# psoc4100sp256kb register map
Vendor: Infineon Technologies; Series: PSOC4100Sp256KB; File version: 1.0
CPU: CM0PLUS r0p1, little endian, MPU, no FPU, VTOR, 2 interrupt priority bits, 29 interrupts
Registers are 32-bit, read-write, reset 0x0 unless marked. A register's access mark holds for its fields unless they carry their own. Offsets are from the block's base; [hi:lo] are bit positions; lines under a group give offsets from that group; {n}, {i} and the like mark numbered series; <NAME> marks a mode.

## PRGIO — Programmable IO configuration
Base 0x40050000
{0x0+0x100*i} PRT[{i}] (i=0..1) group — Programmable IO port registers
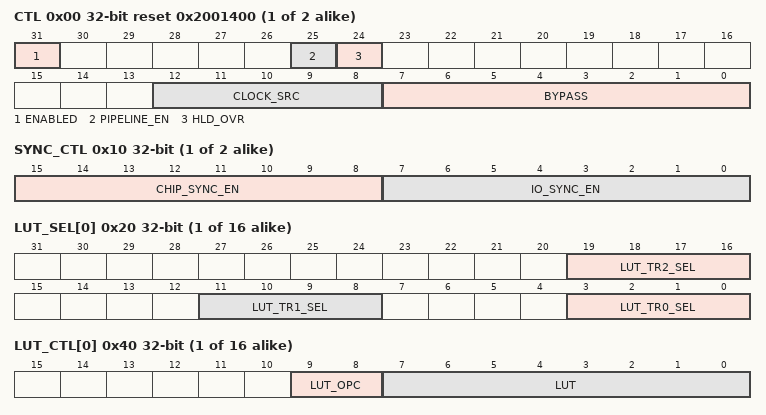
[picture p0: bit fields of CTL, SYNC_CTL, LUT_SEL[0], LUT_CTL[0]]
  0x00 CTL reset 0x2001400 (reset mask 0x82001F00) — Control register
    [31] ENABLED — Enable for programmable IO. Should only be set to '1' when the programmable IO is completely configured: '0': Disabled (signals are bypassed; behavior as if BYPASS is 0xFF). When disabled, the fabric (data unit and LUTs) reset is activated. If the IP is disabled: - The PIPELINE_EN register field should be set to '1', to ensure low power consumption by preventing combinatorial loops. - The CLOCK_SRC register field should be set to '20'-'30' (clock is constant '0'), to ensure low power consumption. '1': Enabled. Once enabled, it takes 3 'clk_fabric' clock cycles till the fabric reset is de-activated and the fabric becomes fully functional. This ensures that the IO pins' input synchronizer states are flushed when the fabric is fully functional.
    [25] PIPELINE_EN — Enable for pipeline register: '0': Disabled (register is bypassed). '1': Enabled.
    [24] HLD_OVR — IO cell hold override functionality. In DeepSleep and Hibernate power modes, the HSIOM holds the IO cell output and output enable signals if Active functionality is connected to the IO pads. This is undesirable if the PRGIO is supposed to deliver DeepSleep or Hibernate output functionality on these IO pads. This field is used to control the hold override functionality from the PRGIO: '0': The HSIOM controls the IO cell hold override functionality ('hsiom_hld_ovr'). '1': The PRGIO controls the IO cel hold override functionality: - In bypass mode (ENABLED is '0' or BYPASS[i] is '1'), the HSIOM control is used. - In NON bypass mode (ENABLED is '1' and BYPASS[i] is '0'), the PRGIO sets hold override to 'pwr_hld_ovr_hib' to enable PRGIO functionality in DeepSleep and Hibernate power modes (but disables it in Stop power mode). Note that in Hibernate power mode, the PRGIO should not rely on the state of Active or DeepSleep functionality signals from the HSIOM: these signals are clamped to '0' in Hibernate'
    [12:8] CLOCK_SRC — Clock ('clk_fabric') and reset ('rst_fabric_n') source selection: '0': io_data_in[0]/'1'. ... '7': io_data_in[7]/'1'. '8': chip_data[0]/'1'. ... '15': chip_data[7]/'1'. '16': clk_prgio/rst_sys_act_n. Used for both Active functionality synchronous logic on 'clk_prgio'. This selection is intended for synchronous operation on a PCLK specified clock frequency ('clock_prgio_en'). Note that the fabric's clocked elements are frequency aligned, but NOT phase aligned to 'clk_sys'. '17': clk_prgio/rst_sys_dpslp_n. Used for both DeepSleep functionality synchronous logic on 'clk_prgio' (note that 'clk_prgio' is NOT available in DeepSleep and Hibernate power modes). This selection is intended for synchronous operation on a PCLK specified clock frequency ('clock_prgio_en'). Note that the fabric's clocked elements are frequency aligned, but NOT phase aligned to 'clk_sys'. '18': clk_prgio/rst_sys_hib_n. Used for both Hibernate functionality synchronous logic on 'clk_prgio' (note that 'clk_prgio' is NOT available in DeepSleep and Hibernate power modes). This selection is intended for synchronous operation on a PCLK specified clock frequency ('clock_prgio_en'). Note that the fabric's clocked elements are frequency aligned, but NOT phase aligned to 'clk_sys'. '19': clk_lf/rst_lf_dpslp_n (note that 'clk_lf' is only available in DeepSleep power mode). This selection is intended for synchronous operation on'clk_lf'. Note that the fabric's clocked elements are frequency aligned, but NOT phase aligned to other 'clk_lf' clocked elements. '20'-'30': Clock source is constant '0'. Any of these clock sources should be selected when the IP is disabled to ensure low power consumption. '31': clk_sys/'1'. This selection is NOT intended for 'clk_sys' operation, but for asynchronous operation: three 'clk_sys' cycles after enabling the IP, the IP is fully functional (reset is de-activated). To be used for asynchronous (clockless) fabric functionality.
    [7:0] BYPASS — Bypass of the programmable IO, one bit for each IO pin: BYPASS[i] is for IO pin i. When ENABLED is '1', this field is used. When ENABLED is '0', this field is NOT used and PRGIO is always bypassed. '0': No bypass (programmable IO fabric is exposed). '1': Bypass (programmable IO fabric is hidden).
  0x10 SYNC_CTL reset not defined — Synchronization control register
    [15:8] CHIP_SYNC_EN — Synchronization of the chip input signals to 'clk_fabric', one bit for each input: CHIP_SYNC_EN[i] is for input i. '0': No synchronization. '1': Synchronization.
    [7:0] IO_SYNC_EN — Synchronization of the IO pin input signals to 'clk_fabric', one bit for each IO pin: IO_SYNC_EN[i] is for IO pin i. '0': No synchronization. '1': Synchronization.
  {0x20+4j} LUT_SEL[{j}] (j=0..7) reset not defined — LUT component input selection
    [19:16] LUT_TR2_SEL — LUT input signal 'tr2_in' source selection. Encoding is the same as for LUT_TR1_SEL.
    [11:8] LUT_TR1_SEL — LUT input signal 'tr1_in' source selection: '0': LUT 0 output. '1': LUT 1 output. '2': LUT 2 output. '3': LUT 3 output. '4': LUT 4 output. '5': LUT 5 output. '6': LUT 6 output. '7': LUT 7 output. '8': chip_data[0] (for LUTs 0, 1, 2, 3); chip_data[4] (for LUTs 4, 5, 6, 7). '9': chip_data[1] (for LUTs 0, 1, 2, 3); chip_data[5] (for LUTs 4, 5, 6, 7). '10': chip_data[2] (for LUTs 0, 1, 2, 3); chip_data[6] (for LUTs 4, 5, 6, 7). '11': chip_data[3] (for LUTs 0, 1, 2, 3); chip_data[7] (for LUTs 4, 5, 6, 7). '12': io_data_in[0] (for LUTs 0, 1, 2, 3); io_data_in[4] (for LUTs 4, 5, 6, 7). '13': io_data_in[1] (for LUTs 0, 1, 2, 3); io_data_in[5] (for LUTs 4, 5, 6, 7). '14': io_data_in[2] (for LUTs 0, 1, 2, 3); io_data_in[6] (for LUTs 4, 5, 6, 7). '15': io_data_in[3] (for LUTs 0, 1, 2, 3); io_data_in[7] (for LUTs 4, 5, 6, 7).
    [3:0] LUT_TR0_SEL — LUT input signal 'tr0_in' source selection: '0': Data unit output. '1': LUT 1 output. '2': LUT 2 output. '3': LUT 3 output. '4': LUT 4 output. '5': LUT 5 output. '6': LUT 6 output. '7': LUT 7 output. '8': chip_data[0] (for LUTs 0, 1, 2, 3); chip_data[4] (for LUTs 4, 5, 6, 7). '9': chip_data[1] (for LUTs 0, 1, 2, 3); chip_data[5] (for LUTs 4, 5, 6, 7). '10': chip_data[2] (for LUTs 0, 1, 2, 3); chip_data[6] (for LUTs 4, 5, 6, 7). '11': chip_data[3] (for LUTs 0, 1, 2, 3); chip_data[7] (for LUTs 4, 5, 6, 7). '12': io_data_in[0] (for LUTs 0, 1, 2, 3); io_data_in[4] (for LUTs 4, 5, 6, 7). '13': io_data_in[1] (for LUTs 0, 1, 2, 3); io_data_in[5] (for LUTs 4, 5, 6, 7). '14': io_data_in[2] (for LUTs 0, 1, 2, 3); io_data_in[6] (for LUTs 4, 5, 6, 7). '15': io_data_in[3] (for LUTs 0, 1, 2, 3); io_data_in[7] (for LUTs 4, 5, 6, 7).
  {0x40+4j} LUT_CTL[{j}] (j=0..7) reset not defined — LUT component control register
    [9:8] LUT_OPC — LUT opcode specifies the LUT operation: '0': Combinatoral output, no feedback. tr_out = LUT[{tr2_in, tr1_in, tr0_in}]. '1': Combinatorial output, feedback. tr_out = LUT[{lut_reg, tr1_in, tr0_in}]. On clock: lut_reg <= tr_in2. '2': Sequential output, no feedback. temp = LUT[{tr2_in, tr1_in, tr0_in}]. tr_out = lut_reg. On clock: lut_reg <= temp. '3': Register with asynchronous set and reset. tr_out = lut_reg. enable = (tr2_in ^ LUT[4]) | LUT[5]. set = enable & (tr1_in ^ LUT[2]) & LUT[3]. clr = enable & (tr0_in ^ LUT[0]) & LUT[1]. Asynchronously (no clock required): lut_reg <= if (clr) '0' else if (set) '1'
    [7:0] LUT — LUT configuration. Depending on the LUT opcode LUT_OPC, the internal state lut_reg (captured in a flip-flop) and the LUT input signals tr0_in, tr1_in, tr2_in, the LUT configuration is used to determine the LUT output signal and the next sequential state (lut_reg).
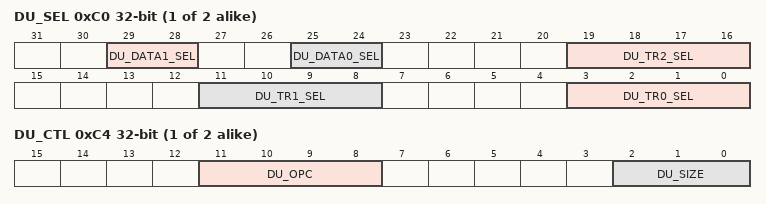
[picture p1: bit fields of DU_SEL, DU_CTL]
  0xC0 DU_SEL reset not defined — Data unit component input selection
    [29:28] DU_DATA1_SEL — Data unit input data 'data1_in' source selection. Encoding is the same as for DU_DATA0_SEL.
    [25:24] DU_DATA0_SEL — Data unit input data 'data0_in' source selection: '0': Constant '0'. '1': chip_data[7:0]. '2': io_data_in[7:0]. '3': DATA.DATA MMIO register field.
    [19:16] DU_TR2_SEL — Data unit input signal 'tr2_in' source selection. Encoding is the same as for DU_TR0_SEL.
    [11:8] DU_TR1_SEL — Data unit input signal 'tr1_in' source selection. Encoding is the same as for DU_TR0_SEL.
    [3:0] DU_TR0_SEL — Data unit input signal 'tr0_in' source selection: '0': Constant '0'. '1': Constant '1'. '2': Data unit output. '10-3': LUT 7 - 0 outputs. Otherwise: Undefined.
  0xC4 DU_CTL reset not defined — Data unit component control register
    [11:8] DU_OPC — Data unit opcode specifies the data unit operation: '1': INCR '2': DECR '3': INCR_WRAP '4': DECR_WRAP '5': INCR_DECR '6': INCR_DECR_WRAP '7': ROR '8': SHR '9': AND_OR '10': SHR_MAJ3 '11': SHR_EQL. Otherwise: Undefined.
    [2:0] DU_SIZE — Size/width of the data unit data operands (in bits) is DU_SIZE+1. E.g., if DU_SIZE is 7, the width is 8 bits.
  0xF0 DATA reset not defined
    [7:0] DATA — Data unit input data source.
